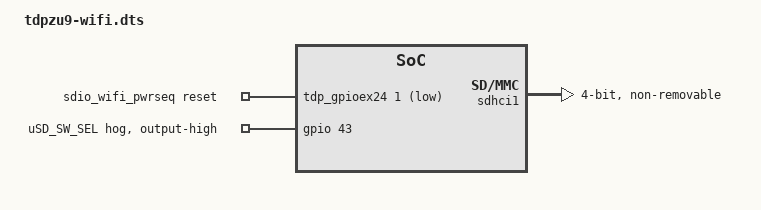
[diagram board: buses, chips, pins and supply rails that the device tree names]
/*
 * dts file for tdpzu9 (Topic Developmentkit Plus) board without PL
 *
 * (C) Copyright 2020, Topic Embedded Products BV
 *
 * This program is free software; you can redistribute it and/or
 * modify it under the terms of the GNU General Public License as
 * published by the Free Software Foundation; either version 2 of
 * the License, or (at your option) any later version.
 */

#include "tdpzu9.dts"

/ {
	sdio_wifi_pwrseq: sdio_wifi_pwrseq {
		compatible = "mmc-pwrseq-simple";
		reset-gpios = <&tdp_gpioex24 1 GPIO_ACTIVE_LOW>;
		post-power-on-delay-ms = <1>; /* 100 us according to datasheet */
	};
};

&tdp_gpioex24 {
	/delete-node/ wifi-en;
};

&gpio {
	/* Set SW switch to WIFI position */
	/delete-node/ usd-sw-sel;
	usd-sw-sel {
		gpio-hog;
		gpios = <43 0>;
		output-high;
		line-name = "uSD_SW_SEL";
	};
};

/* Set the SD1 controller switches to WIFI */
&sdhci1 {
	status = "okay";
	xlnx,mio_bank = <1>;
	disable-wp;
	bus-width = <4>;
	non-removable; /* WiFi is soldered on */
	no-1-8-v; /* No high-speed capability */
	mmc-pwrseq = <&sdio_wifi_pwrseq>;
	/delete-property/ cd-gpios;
	/delete-property/ vqmmc-supply;
};


&pinctrl_sdhci1_default {
	/delete-node/ mux-wp;
	/delete-node/ conf-wp;
	conf-cd {
		/delete-property/ bias-pull-up;
		bias-pull-down;
	};
	mux-wp {
		groups = "gpio0_44_grp";
		function = "gpio0";
	};
	conf-wp {
		groups = "gpio0_44_grp";
		slew-rate = <SLEW_RATE_SLOW>;
		io-standard = <IO_STANDARD_LVCMOS33>;
		bias-pull-down;
	};
};
